VERSION ""

NS_ :

BS_:

BU_: BMS VehicleController

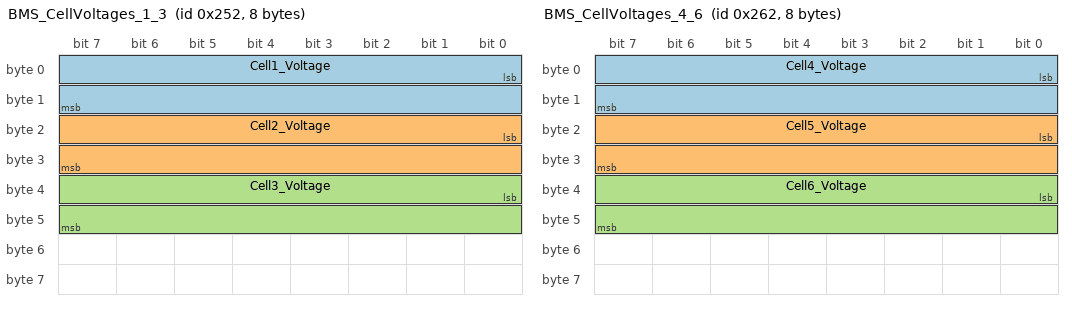
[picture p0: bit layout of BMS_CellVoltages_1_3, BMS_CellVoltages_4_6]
BO_ 594 BMS_CellVoltages_1_3: 8 BMS
 SG_ Cell1_Voltage : 0|16@1+ (0.001,0) [2.5|4.2] "V" VehicleController
 SG_ Cell2_Voltage : 16|16@1+ (0.001,0) [2.5|4.2] "V" VehicleController
 SG_ Cell3_Voltage : 32|16@1+ (0.001,0) [2.5|4.2] "V" VehicleController

BO_ 610 BMS_CellVoltages_4_6: 8 BMS
 SG_ Cell4_Voltage : 0|16@1+ (0.001,0) [2.5|4.2] "V" VehicleController
 SG_ Cell5_Voltage : 16|16@1+ (0.001,0) [2.5|4.2] "V" VehicleController
 SG_ Cell6_Voltage : 32|16@1+ (0.001,0) [2.5|4.2] "V" VehicleController

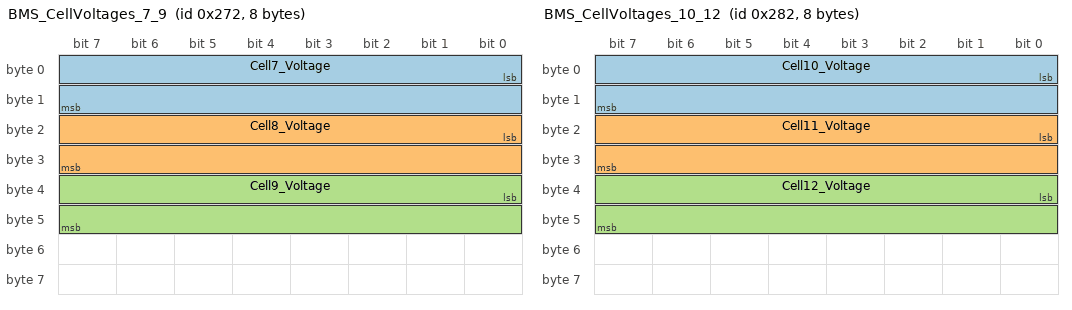
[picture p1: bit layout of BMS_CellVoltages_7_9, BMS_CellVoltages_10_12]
BO_ 626 BMS_CellVoltages_7_9: 8 BMS
 SG_ Cell7_Voltage : 0|16@1+ (0.001,0) [2.5|4.2] "V" VehicleController
 SG_ Cell8_Voltage : 16|16@1+ (0.001,0) [2.5|4.2] "V" VehicleController
 SG_ Cell9_Voltage : 32|16@1+ (0.001,0) [2.5|4.2] "V" VehicleController

BO_ 642 BMS_CellVoltages_10_12: 8 BMS
 SG_ Cell10_Voltage : 0|16@1+ (0.001,0) [2.5|4.2] "V" VehicleController
 SG_ Cell11_Voltage : 16|16@1+ (0.001,0) [2.5|4.2] "V" VehicleController
 SG_ Cell12_Voltage : 32|16@1+ (0.001,0) [2.5|4.2] "V" VehicleController

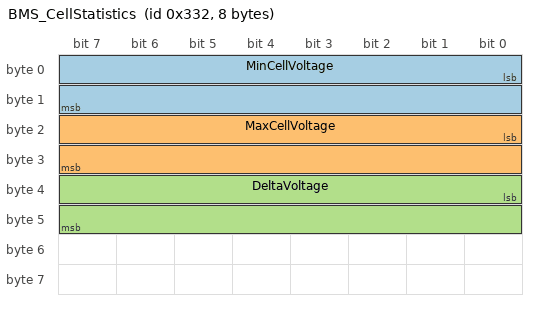
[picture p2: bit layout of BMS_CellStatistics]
BO_ 818 BMS_CellStatistics: 8 BMS
 SG_ MinCellVoltage : 0|16@1+ (0.001,0) [2.5|4.2] "V" VehicleController
 SG_ MaxCellVoltage : 16|16@1+ (0.001,0) [2.5|4.2] "V" VehicleController
 SG_ DeltaVoltage : 32|16@1+ (0.001,0) [0|1] "V" VehicleController
